AUTOSAR XML (schema 00048)
package /ComponentTypes
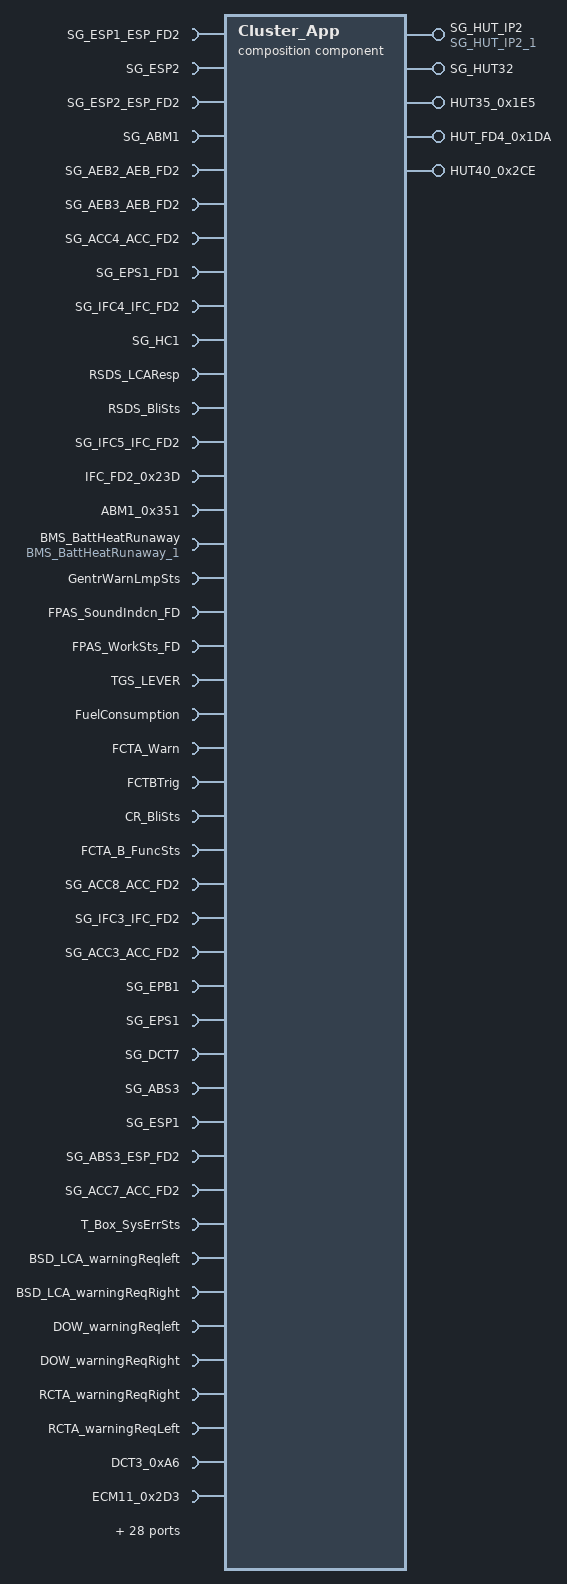
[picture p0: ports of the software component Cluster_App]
  composition sw component type Cluster_App
    33 x require port:
      SG_ESP1_ESP_FD2: nonqueued-receiver-com-spec{data-element=SG_ESP1_ESP_FD2, uses-end-to-end-protection=true, alive-timeout=0.2, enable-update=true, handle-never-received=true, init-value=fields=[BTCActv_0x137:0, CheckSum_ESP1_0x137:0, dummy_ESP_FD2_16:0, dummy_ESP_FD2_17:0, dummy_ESP_FD2_18:0, dummy_ESP_FD2_19:0, dummy_ESP_FD2_20:0, ESP_MasterCylBrkPress_0x137:0, ESP_MasterCylBrkPressVld_0x137:0, ESPActvInfoLmp_0x137:0, ESPBrkLmpCtrl_0x137:0, ESPFailSts_0x137:0, ESPFuncOffSts_0x137:0, MSRActv_0x137:0, PTCActv_0x137:0, RollingCounter_ESP1_0x137:0, VDCActv_0x137:0]}, required-interface=SG_ESP1_ESP_FD2
      SG_ESP2: nonqueued-receiver-com-spec{data-element=SG_ESP2, uses-end-to-end-protection=true, alive-timeout=0.2, enable-update=true, handle-never-received=true, init-value=fields=[DrivingModDis:0, DrivingModReq_ESP:0, TAB_Available:0, TAB_Sts:0, ABAActv_0x145:0, ABAavailable_0x145:0, ABPActv_0x145:0, ABPAvailable_0x145:0, AEBAvailable_0x145:0, AEBBAActv_0x145:0, AEBIBActv_0x145:0, AVHErrSts_0x145:0, AVHSts_0x145:0, AWBActv_0x145:0, AWBAvailable_0x145:0, BrkDskOvrheatd_0x145:0, CDDActv_0x145:0, CDDAvailable_0x145:0, CDPActv_0x145:0, CheckSum_ESP2_0x145:0, dummy_ESP2_0:0, dummy_ESP2_1:0, dummy_ESP2_2:0, dummy_ESP2_3:0, dummy_ESP2_4:0, dummy_ESP2_5:0, dummy_ESP2_6:0, dummy_ESP2_7:0, HDCCtrl_0x145:0, HDCFault_0x145:0, NoBrkForce_0x145:0, RollingCounter_ESP2_0x145:0, VehStandstill_0x145:0]}, required-interface=SG_ESP2
      SG_ESP2_ESP_FD2: nonqueued-receiver-com-spec{data-element=SG_ESP2_ESP_FD2, uses-end-to-end-protection=true, alive-timeout=0.2, enable-update=true, handle-never-received=true, init-value=fields=[ABAActv_0x137:0, ABAavailable_0x137:0, ABPActv_0x137:0, ABPAvailable_0x137:0, AEBAvailable_0x137:0, AEBBAActv_0x137:0, AEBIBActv_0x137:0, AVHErrSts_0x137:0, AVHSts_0x137:0, AWBActv_0x137:0, AWBAvailable_0x137:0, BrkDskOvrheatd_0x137:0, CDDActv_0x137:0, CDDAvailable_0x137:0, CDPActv_0x137:0, CheckSum_ESP2_0x137:0, dummy_ESP_FD2_8:0, dummy_ESP_FD2_9:0, dummy_ESP_FD2_10:0, dummy_ESP_FD2_11:0, dummy_ESP_FD2_12:0, dummy_ESP_FD2_13:0, dummy_ESP_FD2_14:0, dummy_ESP_FD2_15:0, HDCCtrl_0x137:0, HDCFault_0x137:0, NoBrkForce_0x137:0, RollingCounter_ESP2_0x137:0, VehStandstill_0x137:0]}, required-interface=SG_ESP2_ESP_FD2
      SG_ABM1: nonqueued-receiver-com-spec{data-element=SG_ABM1, uses-end-to-end-protection=true, alive-timeout=5, enable-update=true, handle-never-received=true, init-value=fields=[AirbFailLmpCmd:0, CheckSum_ABM1:0, DrvSBR:0, DrvSBR_Visual:0, PassSBR:0, PassSBR_Visual:0, RollingCounter_ABM1:0, SecRowLSBR:0, SecRowLSBR_Visual:0, SecRowMidSBR:0, SecRowMidSBR_Visual:0, SecRowRSBR:0, SecRowRSBR_Visual:0, CrashOutputSts:0, dummy_ABM1_0:0, dummy_ABM1_1:0, dummy_ABM1_2:0, dummy_ABM1_3:0, dummy_ABM1_4:0, dummy_ABM1_5:0]}, required-interface=SG_ABM1
      SG_AEB2_AEB_FD2: nonqueued-receiver-com-spec{data-element=SG_AEB2_AEB_FD2, uses-end-to-end-protection=true, alive-timeout=0.5, enable-update=true, handle-never-received=true, init-value=fields=[AEB_JA_Resp:1, AEB_PedResp:1, AEB_VehResp:1, Checksum_AEB2:0, FCW_Snvty:0, RollingCounter_AEB2:0, dummy_AEB_FD2_8:0, dummy_AEB_FD2_9:0, dummy_AEB_FD2_10:0, dummy_AEB_FD2_11:0, dummy_AEB_FD2_12:0, dummy_AEB_FD2_13:0, dummy_AEB_FD2_14:0]}, required-interface=SG_AEB2_AEB_FD2
      SG_AEB3_AEB_FD2: nonqueued-receiver-com-spec{data-element=SG_AEB3_AEB_FD2, uses-end-to-end-protection=true, alive-timeout=0.5, enable-update=true, handle-never-received=true, init-value=fields=[AEB_JA_Warn:0, AEB_JABrkTrig:0, AEB_JAFuncSts:0, AEB_PedTrig:0, AEB_VehTrig:0, Checksum_AEB3:0, FCW_AEB_PedFctSts:0, FCW_AEB_VehFctSts:0, FCW_Warn:0, RollingCounter_AEB3:0, dummy_AEB_FD2_15:0, dummy_AEB_FD2_16:0, dummy_AEB_FD2_17:0, dummy_AEB_FD2_18:0, dummy_AEB_FD2_19:0, dummy_AEB_FD2_20:0, dummy_AEB_FD2_21:0]}, required-interface=SG_AEB3_AEB_FD2
      SG_ACC4_ACC_FD2: nonqueued-receiver-com-spec{data-element=SG_ACC4_ACC_FD2, uses-end-to-end-protection=true, alive-timeout=1, enable-update=true, handle-never-received=true, init-value=fields=[ACC_FctSts:0, ACC_InterSysInfoDisp:0, ACC_ModDisp:0, ACC_ObjDetecte:0, ACC_SpdSetValue:0, ACC_TakeOverReq:0, ACC_TgtObjBarDisp:0, ACC_TimeGapSet:0, Checksum_ACC4:0, ISL_InterSysInfoDisp:0, RollingCounter_ACC4:0, TJA_ACC_SelSts:0, TJA_ICA_InterSysInfoDisp:0, TJA_ICA_ModDisp:0, CruCha_ModDisp:0, CruChar_InterSysInfoDisp:0, Longctrl_HazActv:0, dummy_ACC_FD2_8:0, dummy_ACC_FD2_9:0, dummy_ACC_FD2_10:0]}, required-interface=SG_ACC4_ACC_FD2
      SG_EPS1_FD1: nonqueued-receiver-com-spec{data-element=SG_EPS1_FD1, uses-end-to-end-protection=true, alive-timeout=0.2, enable-update=true, handle-never-received=true, init-value=fields=[CheckSum_EPS1_0x147:0, dummy_EPS_FD1_0:0, dummy_EPS_FD1_1:0, dummy_EPS_FD1_2:0, dummy_EPS_FD1_3:0, dummy_EPS_FD1_4:0, dummy_EPS_FD1_5:0, dummy_EPS_FD1_6:0, dummy_EPS_FD1_7:0, EPS_FailSts_0x147:0, EPS_SteerMod_0x147:0, EPS_TrqSnsrSts_0x147:0, RollingCounter_EPS1_0x147:0]}, required-interface=SG_EPS1_FD1
      SG_IFC4_IFC_FD2: nonqueued-receiver-com-spec{data-element=SG_IFC4_IFC_FD2, uses-end-to-end-protection=true, alive-timeout=0.5, enable-update=true, handle-never-received=true, init-value=fields=[CameraBlockageSts:0, Checksum_IFC4:0, ELKMainState:0, IFC_Handsoffwarn:0, IFCCalibrationSts:0, LaneAvailability:0, LDW_LKAWarn:0, LSSErrSts:0, LSSFuncSts:0, LSSIntervention:0, RollingCounter_IFC4:0, TJA_FollowSts:0, AESintervention:0, ESSintervention:0, dummy_IFC_FD2_13:0, dummy_IFC_FD2_14:0, dummy_IFC_FD2_15:0, ELKActSts:0, IntelligentEvaActSts:0, LCKStsIndcr:0]}, required-interface=SG_IFC4_IFC_FD2
      SG_HC1: nonqueued-receiver-com-spec{data-element=SG_HC1, uses-end-to-end-protection=true, alive-timeout=1, enable-update=true, handle-never-received=true, init-value=fields=[ADBstatus:0, ALS_FailSts:0, Checksum_HC1:0, HighBeamSts_HC:0, LeftHighBeamFailSts:0, LeftLowBeamFailSts:0, RightHighBeamFailSts:0, RightLowBeamFailSts:0, RollingCounter_HC1:0, dummy_HC1_0:0, dummy_HC1_1:0, dummy_HC1_2:0, dummy_HC1_3:0, dummy_HC1_4:0, dummy_HC1_5:0]}, required-interface=SG_HC1
      RSDS_LCAResp: nonqueued-receiver-com-spec{data-element=RSDS_LCAResp, init-value=0}, required-interface=RSDS_LCAResp
      RSDS_BliSts: nonqueued-receiver-com-spec{data-element=RSDS_BliSts, init-value=0}, required-interface=RSDS_BliSts
      SG_IFC5_IFC_FD2: nonqueued-receiver-com-spec{data-element=SG_IFC5_IFC_FD2, init-value=fields=[Checksum_IFC5:0, IFC_LaneCurve:2047, IFC_LeLane_dy:2496, IFC_LeLaneTyp:0, IFC_NextLeLaneTyp:0, IFC_NextRiLaneTyp:0, IFC_RiLane_dy:2496, IFC_RiLaneTyp:0, RollingCounter_IFC5:0, dummy_IFC_FD2_16:0]}, required-interface=SG_IFC5_IFC_FD2
      IFC_FD2_0x23D: nonqueued-receiver-com-spec{data-element=IFC_FD2_0x23D, init-value=64 x 0}, required-interface=IFC_FD2_0x23D
      ABM1_0x351: nonqueued-receiver-com-spec{data-element=ABM1_0x351, init-value=16 x 0}, required-interface=ABM1_0x351
      BMS_BattHeatRunaway: nonqueued-receiver-com-spec{data-element=BMS_BattHeatRunaway, init-value=0}, required-interface=BMS_BattHeatRunaway_1
      GentrWarnLmpSts: nonqueued-receiver-com-spec{data-element=GentrWarnLmpSts, init-value=0}, required-interface=GentrWarnLmpSts
      FPAS_SoundIndcn_FD: nonqueued-receiver-com-spec{data-element=FPAS_SoundIndcn_FD, init-value=0}, required-interface=FPAS_SoundIndcn_FD
      FPAS_WorkSts_FD: nonqueued-receiver-com-spec{data-element=FPAS_WorkSts_FD, filter=data-filter-type=ALWAYS, init-value=0}, required-interface=FPAS_WorkSts_FD
      TGS_LEVER: nonqueued-receiver-com-spec{data-element=TGS_LEVER, init-value=14}, required-interface=TGS_LEVER
      FuelConsumption: nonqueued-receiver-com-spec{data-element=FuelConsumption, init-value=0}, required-interface=FuelConsumption
      FCTA_Warn: nonqueued-receiver-com-spec{data-element=FCTA_Warn, init-value=0}, required-interface=FCTA_Warn
      FCTBTrig: nonqueued-receiver-com-spec{data-element=FCTBTrig, init-value=0}, required-interface=FCTBTrig
      CR_BliSts: nonqueued-receiver-com-spec{data-element=CR_BliSts, init-value=0}, required-interface=CR_BliSts
      FCTA_B_FuncSts: nonqueued-receiver-com-spec{data-element=FCTA_B_FuncSts, init-value=0}, required-interface=FCTA_B_FuncSts
      SG_ACC8_ACC_FD2: nonqueued-receiver-com-spec{data-element=SG_ACC8_ACC_FD2, init-value=fields=[ADAS_DriverInloop_Monitor:0, Checksum_ACC8:0, HWA_InterSysInfoDisp:0, HWA_LaneChange:0, HWA_LaneChangeReq:0, HWA_ModDisp:0, HWA_warning:0, Longctrl_HCUTrqReq_DVR:0, RollingCounter_ACC8:0, dummy_ACC_FD2_11:0, dummy_ACC_FD2_12:0, dummy_ACC_FD2_13:0, dummy_ACC_FD2_14:0, dummy_ACC_FD2_15:0]}, required-interface=SG_ACC8_ACC_FD2
      SG_IFC3_IFC_FD2: nonqueued-receiver-com-spec{data-element=SG_IFC3_IFC_FD2, init-value=fields=[AESErrSts:0, AESResp:0, AESSts:0, Checksum_IFC3:0, ELKResp:0, ESS_Pedresp:0, ESS_Vehresp:0, ESSErrSts:0, ESSSts:0, IFCHUTInterface:0, IntelligentEvaResp:0, LCKResp:0, LDW_LKA_Snvty:0, LDWResp:0, LKAResp:0, LSSResp:0, LSSWarnFormResp:0, RollingCounter_IFC3:0, dummy_IFC_FD2_8:0, dummy_IFC_FD2_9:0, dummy_IFC_FD2_10:0, dummy_IFC_FD2_11:0, dummy_IFC_FD2_12:0]}, required-interface=SG_IFC3_IFC_FD2
      SG_ACC3_ACC_FD2: nonqueued-receiver-com-spec{data-element=SG_ACC3_ACC_FD2, init-value=fields=[ALC_InterSysInfoDisp:0, ALC_Resp:0, Checksum_ACC3:0, HWA_Resp:0, HWA_SnvtySet_Resp:0, ICA_HandsOffResp:0, ISL_Resp:0, Longctrl_Decel_Req_DVR:0, Longctrl_Decel_ReqValue_DVR:0, Longctrl_DecelToStopReq_DVR:0, Longctrl_DrvOFF_Req_DVR:0, Longctrl_EngTrqReq_DVR:32767, Longctrl_EngTrqReqActive_DVR:0, Longctrl_HCUTrqReqActive_DVR:0, Longctrl_ModSts_DVR:0, Longctrl_ParkShiftReq_DVR:0, Longctrl_VehHldReq_DVR:0, RollingCounter_ACC3:0, dummy_ACC_FD2_4:0, dummy_ACC_FD2_5:0, dummy_ACC_FD2_6:0, dummy_ACC_FD2_7:0]}, required-interface=SG_ACC3_ACC_FD2
      SG_EPB1: nonqueued-receiver-com-spec{data-element=SG_EPB1, uses-end-to-end-protection=true, alive-timeout=0.2, enable-update=true, handle-never-received=true, init-value=fields=[CheckSum_EPB1:0, EPBErrSts:0, EPBRedLmpSts:0, EPBSts:0, EPBTextDisp:0, PressBrakePedalPointOut:0, RollingCounter_EPB1:0, dummy_EPB1_0:0, dummy_EPB1_1:0, dummy_EPB1_2:0, dummy_EPB1_3:0, dummy_EPB1_4:0, dummy_EPB1_5:0, dummy_EPB1_6:0, dummy_EPB1_7:0]}, required-interface=SG_EPB1
      SG_EPS1: nonqueued-receiver-com-spec{data-element=SG_EPS1, uses-end-to-end-protection=true, alive-timeout=0.2, enable-update=true, handle-never-received=true, init-value=fields=[CheckSum_EPS1_0x168:0, dummy_EPS1_0:0, dummy_EPS1_1:0, dummy_EPS1_2:0, dummy_EPS1_3:0, dummy_EPS1_4:0, dummy_EPS1_5:0, dummy_EPS1_6:0, dummy_EPS1_7:0, EPS_FailSts_0x168:0, EPS_SteerMod_0x168:0, EPS_TrqSnsrSts_0x168:1, RollingCounter_EPS1_0x168:0]}, required-interface=SG_EPS1
      SG_DCT7: nonqueued-receiver-com-spec{data-element=SG_DCT7, uses-end-to-end-protection=true, alive-timeout=0.5, enable-update=true, handle-never-received=true, init-value=fields=[CheckSum_DCT7:0, DCT_PrsBrk_Warn:0, DCT_RaceModeSts:0, DCT_ShftNotAlwd_Warn:0, DCT_ShftRecom_M:0, DrvAutoGearDisp:0, DrvWarnMsg:0, RollingCounter_DCT7:0, DrvFaiMsg_0x235:0, DrvGearDispSts_0x235:0, DrvModDisp_0x235:0, DrvModDispSts_0x235:0, dummy_DCT7_0:0, dummy_DCT7_1:0, dummy_DCT7_2:0, dummy_DCT7_3:0, dummy_DCT7_4:0, dummy_DCT7_5:0]}, required-interface=SG_DCT7
      SG_ABS3: nonqueued-receiver-com-spec{data-element=SG_ABS3, uses-end-to-end-protection=true, alive-timeout=0.2, enable-update=true, handle-never-received=true, init-value=fields=[ABSActv_0x265:0, ABSFailSts_0x265:1, CheckSum_ABS3_0x265:0, dummy_ABS3_0:0, dummy_ABS3_1:0, dummy_ABS3_2:0, dummy_ABS3_3:0, EBDActv_0x265:0, EBDFailSts_0x265:0, RollingCounter_ABS3_0x265:0, VehOdoInfo_0x265:0, VehOdoInfoSts_0x265:1, VehSpd_0x265:0, VehSpdVld_0x265:0]}, required-interface=SG_ABS3
      SG_ESP1: nonqueued-receiver-com-spec{data-element=SG_ESP1, uses-end-to-end-protection=true, alive-timeout=0.2, enable-update=true, handle-never-received=true, init-value=fields=[BTCActv_0x149:0, CheckSum_ESP1_0x149:0, dummy_ESP1_0:0, dummy_ESP1_1:0, dummy_ESP1_2:0, dummy_ESP1_3:0, dummy_ESP1_4:0, ESP_MasterCylBrkPress_0x149:0, ESP_MasterCylBrkPressVld_0x149:1, ESPActvInfoLmp_0x149:0, ESPBrkLmpCtrl_0x149:0, ESPFailSts_0x149:0, ESPFuncOffSts_0x149:0, MSRActv_0x149:0, PTCActv_0x149:0, RollingCounter_ESP1_0x149:0, VDCActv_0x149:0]}, required-interface=SG_ESP1
    provide port SG_HUT_IP2: nonqueued-sender-com-spec{data-element=SG_HUT_IP2, uses-end-to-end-protection=true, init-value=fields=[CheckSum_IP2:0, IP_ABMWarnLmpFailrSts:0, IP_ACCErr:0, IP_BattChrgLmpSts:0, IP_DrvSeatBeltWarnLmpFailSts:0, IP_EngOilPressLowLmpSts:0, IP_Err:0, IP_FuelLvlInfo:0, IP_FuelLvlLowLmpSts:0, IP_PassSeatBeltWarnLmpFailSts:0, IP_VehSpdUnit:0, IP_VehTotDistance:0, IP_VehTotDistanceValid:0, IP_VINcompr:0, RollingCounter_IP2:0]}, provided-interface=SG_HUT_IP2_1
    11 x require port:
      SG_ABS3_ESP_FD2: nonqueued-receiver-com-spec{data-element=SG_ABS3_ESP_FD2, uses-end-to-end-protection=true, alive-timeout=0.2, enable-update=true, handle-never-received=true, init-value=fields=[ABSActv_0x137:0, ABSFailSts_0x137:1, CheckSum_ABS3_0x137:0, dummy_ESP_FD2_37:0, dummy_ESP_FD2_38:0, dummy_ESP_FD2_39:0, dummy_ESP_FD2_40:0, EBDActv_0x137:0, EBDFailSts_0x137:0, RollingCounter_ABS3_0x137:0, VehOdoInfo_0x137:0, VehOdoInfoSts_0x137:1, VehSpd_0x137:0, VehSpdVld_0x137:0]}, required-interface=SG_ABS3_ESP_FD2
      SG_ACC7_ACC_FD2: nonqueued-receiver-com-spec{data-element=SG_ACC7_ACC_FD2, uses-end-to-end-protection=true, alive-timeout=1, enable-update=true, handle-never-received=true, init-value=fields=[ACC_LeTargrtDection:0, ACC_LeTgtDx:0, ACC_LeTgtDy:0, ACC_LeTgtTyp:0, ACC_RiTargrtDetn:0, ACC_RiTgtDx:0, ACC_RiTgtDy:0, ACC_RiTgtTyp:0, Checksum_ACC7:0, dummy_ACC_FD2_19:0, dummy_ACC_FD2_20:0, Request_driveoff:0, RollingCounter_ACC7:0]}, required-interface=SG_ACC7_ACC_FD2
      T_Box_SysErrSts: nonqueued-receiver-com-spec{data-element=T_Box_SysErrSts, init-value=0}, required-interface=T_Box_SysErrSts
      BSD_LCA_warningReqleft: nonqueued-receiver-com-spec{data-element=BSD_LCA_warningReqleft, init-value=0}, required-interface=BSD_LCA_warningReqleft
      BSD_LCA_warningReqRight: nonqueued-receiver-com-spec{data-element=BSD_LCA_warningReqRight, init-value=0}, required-interface=BSD_LCA_warningReqRight
      DOW_warningReqleft: nonqueued-receiver-com-spec{data-element=DOW_warningReqleft, init-value=0}, required-interface=DOW_warningReqleft
      DOW_warningReqRight: nonqueued-receiver-com-spec{data-element=DOW_warningReqRight, init-value=0}, required-interface=DOW_warningReqRight
      RCTA_warningReqRight: nonqueued-receiver-com-spec{data-element=RCTA_warningReqRight, init-value=0}, required-interface=RCTA_warningReqRight
      RCTA_warningReqLeft: nonqueued-receiver-com-spec{data-element=RCTA_warningReqLeft, init-value=0}, required-interface=RCTA_warningReqLeft
      DCT3_0xA6: nonqueued-receiver-com-spec{data-element=DCT3_0xA6, init-value=8 x 0}, required-interface=DCT3_0xA6
      ECM11_0x2D3: nonqueued-receiver-com-spec{data-element=ECM11_0x2D3, init-value=8 x 0}, required-interface=ECM11_0x2D3
    provide port SG_HUT32: nonqueued-sender-com-spec{data-element=SG_HUT32, uses-end-to-end-protection=true, init-value=fields=[CheckSum_HUT32:0, ContnPrkgReq:0, ContnPrkgReqValid:0, DetVideoLost:0, PrkgCtrlModReq:0, PrkgCtrlModReqValid:0, PrkStraightContinueReq_HUT:0, PrkStraightModSel_HUT:0, PrkStraightStrtReq_HUT:0, PrkStraightSts_HUT:0, PrkStraightSuspendOrFinishReq_HUT:0, PrkStraightSwtReq_HUT:0, PrkStraightVehStrtReq_HUT_Valid:0, RollingCounter_HUT32:0, ScrnOpSts:0, VolLampDispSts:0, XLvl:2047, YLvl:2047]}, provided-interface=SG_HUT32
    8 x require port:
      ACC_FD4_0x2B8: nonqueued-receiver-com-spec{data-element=ACC_FD4_0x2B8, alive-timeout=1, enable-update=true, filter=data-filter-type=ALWAYS, handle-never-received=true, init-value=64 x 0}, required-interface=ACC_FD4_0x2B8
      SG_ACC6_ACC_FD2: nonqueued-receiver-com-spec{data-element=SG_ACC6_ACC_FD2, uses-end-to-end-protection=true, alive-timeout=1, enable-update=true, filter=data-filter-type=ALWAYS, handle-never-received=true, init-value=fields=[ACC_EgoStatus:0, ACC_PotentialTgtDetn:0, ACC_PotentialTgtDx:0, ACC_PotentialTgtDy:0, ACC_PotentialTgtTyp:0, ACC_RlvTgtDetn:0, ACC_RlvTgtDx:0, ACC_RlvTgtDy:0, ACC_RlvTgtTyp:0, Checksum_ACC6:0, dummy_ACC_FD2_16:0, dummy_ACC_FD2_17:0, dummy_ACC_FD2_18:0, RollingCounter_ACC6:0]}, required-interface=SG_ACC6_ACC_FD2
      SG_BMS4: nonqueued-receiver-com-spec{data-element=SG_BMS4, uses-end-to-end-protection=true, alive-timeout=0.1, enable-update=true, filter=data-filter-type=ALWAYS, handle-never-received=true, init-value=fields=[BMS_BattPoweErr:0, BMS_ErrCategory:0, BMS_PackCurr:0, BMS_PackVolt:178, BMS_PowerDownCmplt:0, CheckSum_BMS4:0, dummy_BMS4_0:0, dummy_BMS4_1:0, dummy_BMS4_2:0, dummy_BMS4_3:0, dummy_BMS4_4:0, RollingCounter_BMS4:0]}, required-interface=SG_BMS4
      SG_HCU_HP5: nonqueued-receiver-com-spec{data-element=SG_HCU_HP5, uses-end-to-end-protection=true, alive-timeout=0.5, enable-update=true, filter=data-filter-type=ALWAYS, handle-never-received=true, init-value=fields=[Checksum_HCU_HP5:0, DrvFaiMsg_0x201:0, DrvGearDisp:0, DrvGearDispSts_0x201:0, DrvModDisp_0x201:0, DrvModDispSts_0x201:0, dummy_HCU_HP5_0:0, dummy_HCU_HP5_1:0, dummy_HCU_HP5_2:0, dummy_HCU_HP5_3:0, dummy_HCU_HP5_4:0, HCU_EnrgFlowInd_DHT:0, HCU_PrsBrkWarn:0, HCU_ShftNotAlwd_Warn:0, RollingCounter_HCU_HP5:0]}, required-interface=SG_HCU_HP5
      SG_HCU_PT4: nonqueued-receiver-com-spec{data-element=SG_HCU_PT4, uses-end-to-end-protection=true, alive-timeout=1, enable-update=true, filter=data-filter-type=ALWAYS, handle-never-received=true, init-value=fields=[CarWashMode_Sts:0, CarWashMode_StsDisp:0, Checksum_HCU_PT4:0, dummy_HCU_PT4_0:0, dummy_HCU_PT4_1:0, dummy_HCU_PT4_2:0, dummy_HCU_PT4_3:0, dummy_HCU_PT4_4:0, dummy_HCU_PT4_5:0, dummy_HCU_PT4_6:0, dummy_HCU_PT4_7:0, HCU_ACStsReq:2, HCU_BattPowerRedWarn:0, HCU_ConnectChrgLine_Indcn:0, HCU_EgyRecFB:0, HCU_EnerSavePowerMod:0, HCU_InhbChrgInfo:0, HCU_OilTankCoverSts:0, HCU_OPDFail:0, HCU_RefuReq:0, HCU_RemoveChrgLine_Indcn:0, HCU_Shift_P_Indcn:0, HCU_SOCLow_Indcn:0, HCU_WadeModeSetSts:0, OPDParkWarnReq:0, RollingCounter_HCU_PT4:0]}, required-interface=SG_HCU_PT4
      SG_HCU_PT7: nonqueued-receiver-com-spec{data-element=SG_HCU_PT7, uses-end-to-end-protection=true, alive-timeout=0.5, enable-update=true, filter=data-filter-type=ALWAYS, handle-never-received=true, init-value=fields=[CheckSum_HCU_PT7:0, dummy_HCU_PT7_0:0, dummy_HCU_PT7_1:0, dummy_HCU_PT7_2:0, dummy_HCU_PT7_3:0, dummy_HCU_PT7_4:0, dummy_HCU_PT7_5:0, dummy_HCU_PT7_6:0, HCU_12VSysErr_1:0, HCU_12VSysErr_2:0, HCU_12VSysErrLmpSts:0, HCU_EnrgFlowInd:0, HCU_HybSysErr_1:0, HCU_HybSysErr_2:0, HCU_HybSysErr_3:0, HCU_HybSysErr_4:0, HCU_HybSysErr_5:0, HCU_HybSysErr_6:0, HCU_HybSysErr_7:0, HCU_HybSysErrLmpSts:0, HCU_ModSwtFail:0, HCU_OPDLmpSts:0, HCU_OPDSts:0, HCU_PowerRedWarnLmpCmd:0, HCU_RdyLmpSts:0, RollingCounter_HCU_PT7:0]}, required-interface=SG_HCU_PT7
      SG_DHT_FD1: nonqueued-receiver-com-spec{data-element=SG_DHT_FD1, uses-end-to-end-protection=true, alive-timeout=0.1, enable-update=true, filter=data-filter-type=ALWAYS, handle-never-received=true, init-value=fields=[CheckSum_DHT1:0, dummy_DHT_FD1_8:0, dummy_DHT_FD1_9:0, dummy_DHT_FD1_10:0, dummy_DHT_FD1_11:0, dummy_DHT_FD1_12:0, dummy_DHT_FD1_13:0, RollingCounter_DHT1:0, TCU_ClutchHotWarning:0, TCU_ErrCategory:0]}, required-interface=SG_DHT_FD1
      SG_IFC6_IFC_FD2: nonqueued-receiver-com-spec{data-element=SG_IFC6_IFC_FD2, uses-end-to-end-protection=true, alive-timeout=0.5, enable-update=true, filter=data-filter-type=ALWAYS, handle-never-received=true, init-value=fields=[Checksum_IFC6:0, dummy_IFC_FD2_17:0, dummy_IFC_FD2_18:0, dummy_IFC_FD2_19:0, dummy_IFC_FD2_20:0, IFC_NextLeLane_dy:2496, IFC_NextRiLane_dy:2496, RollingCounter_IFC6:0]}, required-interface=SG_IFC6_IFC_FD2
    provide port HUT35_0x1E5: nonqueued-sender-com-spec{data-element=HUT35_0x1E5, init-value=8 x 0}, provided-interface=HUT35_0x1E5
    provide port HUT_FD4_0x1DA: nonqueued-sender-com-spec{data-element=HUT_FD4_0x1DA, init-value=64 x 0}, provided-interface=HUT_FD4_0x1DA
    require port HAP_FD6_0x289: nonqueued-receiver-com-spec{data-element=HAP_FD6_0x289, uses-end-to-end-protection=true, alive-timeout=1, enable-update=true, filter=data-filter-type=ALWAYS, handle-never-received=true, init-value=64 x 0}, required-interface=HAP_FD6_0x289
    require port HAP_FD7_0x29B: nonqueued-receiver-com-spec{data-element=HAP_FD7_0x29B, alive-timeout=1, enable-update=true, filter=data-filter-type=ALWAYS, handle-never-received=true, init-value=64 x 0}, required-interface=HAP_FD7_0x29B
    provide port HUT40_0x2CE: nonqueued-sender-com-spec{data-element=HUT40_0x2CE, init-value=8 x 0}, provided-interface=HUT40_0x2CE
    18 x require port:
      HCM_L1_0x308: nonqueued-receiver-com-spec{data-element=HCM_L1_0x308, alive-timeout=2, enable-update=true, filter=data-filter-type=ALWAYS, handle-never-received=true, init-value=8 x 0}, required-interface=HCM_L1_0x308
      HCM_R1_0x30D: nonqueued-receiver-com-spec{data-element=HCM_R1_0x30D, alive-timeout=2, enable-update=true, filter=data-filter-type=ALWAYS, handle-never-received=true, init-value=8 x 0}, required-interface=HCM_R1_0x30D
      BMS22_0x3BF: nonqueued-receiver-com-spec{data-element=BMS22_0x3BF, alive-timeout=10, enable-update=true, filter=data-filter-type=ALWAYS, handle-never-received=true, init-value=8 x 0}, required-interface=BMS22_0x3BF
      BMS8_0x285: nonqueued-receiver-com-spec{data-element=BMS8_0x285, alive-timeout=1, enable-update=true, filter=data-filter-type=ALWAYS, handle-never-received=true, init-value=8 x 0}, required-interface=BMS8_0x285
      BMS_FD14_0x1E3: nonqueued-receiver-com-spec{data-element=BMS_FD14_0x1E3, init-value=8 x 0}, required-interface=BMS_FD14_0x1E3
      HCU_FD1_0x60: nonqueued-receiver-com-spec{data-element=HCU_FD1_0x60, alive-timeout=0.1, enable-update=true, filter=data-filter-type=ALWAYS, handle-never-received=true, init-value=64 x 0}, required-interface=HCU_FD1_0x60
      HCU_HC3_0x268: nonqueued-receiver-com-spec{data-element=HCU_HC3_0x268, alive-timeout=0.5, enable-update=true, filter=data-filter-type=ALWAYS, handle-never-received=true, init-value=8 x 0}, required-interface=HCU_HC3_0x268
      HCU_HC8_0x1E2: nonqueued-receiver-com-spec{data-element=HCU_HC8_0x1E2, filter=data-filter-type=ALWAYS, init-value=8 x 0}, required-interface=HCU_HC8_0x1E2
      HCU_HP5_0x201: nonqueued-receiver-com-spec{data-element=HCU_HP5_0x201, alive-timeout=0.5, enable-update=true, filter=data-filter-type=ALWAYS, handle-never-received=true, init-value=8 x 0}, required-interface=HCU_HP5_0x201
      HCU_HP6_0x11A: nonqueued-receiver-com-spec{data-element=HCU_HP6_0x11A, alive-timeout=0.2, enable-update=true, filter=data-filter-type=ALWAYS, handle-never-received=true, init-value=8 x 0}, required-interface=HCU_HP6_0x11A
      FPAS_WorkSts: nonqueued-receiver-com-spec{data-element=FPAS_WorkSts, alive-timeout=1, enable-update=true, filter=data-filter-type=ALWAYS, handle-never-received=true, init-value=0}, required-interface=FPAS_WorkSts
      FPAS_SoundIndcn: nonqueued-receiver-com-spec{data-element=FPAS_SoundIndcn, alive-timeout=1, enable-update=true, filter=data-filter-type=ALWAYS, handle-never-received=true, init-value=0}, required-interface=FPAS_SoundIndcn
      RPAS_SoundIndcn: nonqueued-receiver-com-spec{data-element=RPAS_SoundIndcn, alive-timeout=1, enable-update=true, filter=data-filter-type=ALWAYS, handle-never-received=true, init-value=0}, required-interface=RPAS_SoundIndcn
      RPAS_WorkSts: nonqueued-receiver-com-spec{data-element=RPAS_WorkSts, alive-timeout=1, enable-update=true, filter=data-filter-type=ALWAYS, handle-never-received=true, init-value=0}, required-interface=RPAS_WorkSts
      LADBstatus: nonqueued-receiver-com-spec{data-element=LADBstatus, alive-timeout=2, enable-update=true, filter=data-filter-type=ALWAYS, handle-never-received=true, init-value=0}, required-interface=LADBstatus
      RADBstatus: nonqueued-receiver-com-spec{data-element=RADBstatus, alive-timeout=2, enable-update=true, filter=data-filter-type=ALWAYS, handle-never-received=true, init-value=0}, required-interface=RADBstatus
      LHiBeamSts: nonqueued-receiver-com-spec{data-element=LHiBeamSts, alive-timeout=2, enable-update=true, filter=data-filter-type=ALWAYS, handle-never-received=true, init-value=0}, required-interface=LHiBeamSts
      RHiBeamSts: nonqueued-receiver-com-spec{data-element=RHiBeamSts, alive-timeout=2, enable-update=true, filter=data-filter-type=ALWAYS, handle-never-received=true, init-value=0}, required-interface=RHiBeamSts
    component Common_Normal: type=Common_Normal
    component Common_GateWay: type=Common_GateWay
    component Common_Safety: type=Common_Safety
    delegate Common_Safety.SG_ESP1_ESP_FD2 <-> outer port SG_ESP1_ESP_FD2
    delegate Common_Normal.SG_IFC4_IFC_FD2 <-> outer port SG_IFC4_IFC_FD2
    connect Common_Normal.ppCS_SWCNormal_DM_API_vGetDrvModTTStatus -> Common_Normal.rpCS_SWCNormal_DM_API_vGetDrvModTTStatus
    connect Common_Normal.ppCS_SWCNormal_DM_API_vGetDrvModWarningStatus -> Common_Normal.rpCS_SWCNormal_DM_API_vGetDrvModWarningStatus
    connect Common_Normal.ppSR_SWCNormal_SpeedoInfo -> Common_Normal.rpSR_SWCNormal_SpeedoInfo
    connect Common_Normal.ppSR_SWCNormal_TachoInfo -> Common_Normal.rpSR_SWCNormal_TachoInfo
    connect Common_Normal.ppSR_SWCNormal_OdoParament -> Common_Normal.rpSR_SWCNormal_OdoParament
    connect Common_Normal.ppSR_SWCNormal_Fuel_Set_Module_Data -> Common_Normal.rpSR_SWCNormal_Fuel_Set_Module_Data
    connect Common_Normal.ppSR_SWCNormal_TC_Module_Output_Data -> Common_Normal.rpSR_SWCNormal_TC_Module_Output_Data
    connect Common_Normal.ppCS_SWCNormal_Reset_TC_Module_Data -> Common_Normal.rpCS_SWCNormal_Reset_TC_Module_Data
    connect Common_Normal.svCS_SWCNormal_ReceiveMenuSetting -> Common_GateWay.rcCS_SWCNormal_ReceiveMenuSetting
    connect Common_Normal.svCS_SWCNormal_HMIResetTC -> Common_GateWay.rcCS_SWCNormal_HMIResetTC
    delegate Common_Normal.SG_HC1 <-> outer port SG_HC1
    delegate Common_Safety.SG_ESP1 <-> outer port SG_ESP1
    delegate Common_GateWay.SG_HUT_IP2 <-> outer port SG_HUT_IP2
    delegate Common_GateWay.SG_ACC7_ACC_FD2 <-> outer port SG_ACC7_ACC_FD2
    delegate Common_Normal.T_Box_SysErrSts <-> outer port T_Box_SysErrSts
    delegate Common_Normal.BSD_LCA_warningReqRight <-> outer port BSD_LCA_warningReqRight
    delegate Common_Normal.BSD_LCA_warningReqleft <-> outer port BSD_LCA_warningReqleft
    delegate Common_Normal.DOW_warningReqleft <-> outer port DOW_warningReqleft
    delegate Common_Normal.DOW_warningReqRight <-> outer port DOW_warningReqRight
    delegate Common_Normal.RCTA_warningReqLeft <-> outer port RCTA_warningReqLeft
    delegate Common_Normal.RCTA_warningReqRight <-> outer port RCTA_warningReqRight
    delegate Common_Safety.SG_AEB2_AEB_FD2 <-> outer port SG_AEB2_AEB_FD2
    delegate Common_Safety.SG_AEB3_AEB_FD2 <-> outer port SG_AEB3_AEB_FD2
    delegate Common_Safety.SG_EPS1_FD1 <-> outer port SG_EPS1_FD1
    delegate Common_Safety.SG_ESP2_ESP_FD2 <-> outer port SG_ESP2_ESP_FD2
    delegate Common_Safety.SG_ABM1 <-> outer port SG_ABM1
    delegate Common_Safety.SG_ABS3_ESP_FD2 <-> outer port SG_ABS3_ESP_FD2
    delegate Common_Safety.SG_DCT7 <-> outer port SG_DCT7
    delegate Common_Safety.SG_EPB1 <-> outer port SG_EPB1
    delegate Common_Safety.SG_EPS1 <-> outer port SG_EPS1
    delegate Common_Safety.SG_ESP2 <-> outer port SG_ESP2
    delegate Common_Safety.SG_ABS3 <-> outer port SG_ABS3
    delegate Common_GateWay.DCT3_0xA6 <-> outer port DCT3_0xA6
    delegate Common_GateWay.ECM11_0x2D3 <-> outer port ECM11_0x2D3
    delegate Common_GateWay.SG_HUT32 <-> outer port SG_HUT32
    delegate Common_GateWay.ACC_FD4_0x2B8 <-> outer port ACC_FD4_0x2B8
    delegate Common_GateWay.SG_ACC6_ACC_FD2 <-> outer port SG_ACC6_ACC_FD2
    delegate Common_GateWay.SG_ACC8_ACC_FD2 <-> outer port SG_ACC8_ACC_FD2
    delegate Common_GateWay.SG_ACC3_ACC_FD2 <-> outer port SG_ACC3_ACC_FD2
    delegate Common_GateWay.SG_ACC4_ACC_FD2 <-> outer port SG_ACC4_ACC_FD2
    delegate Common_GateWay.HUT35_0x1E5 <-> outer port HUT35_0x1E5
    delegate Common_GateWay.HUT_FD4_0x1DA <-> outer port HUT_FD4_0x1DA
    delegate Common_GateWay.HAP_FD6_0x289 <-> outer port HAP_FD6_0x289
    delegate Common_GateWay.HUT40_0x2CE <-> outer port HUT40_0x2CE
    delegate Common_GateWay.HCM_R1_0x30D <-> outer port HCM_R1_0x30D
    delegate Common_GateWay.HCM_L1_0x308 <-> outer port HCM_L1_0x308
    delegate Common_GateWay.HAP_FD7_0x29B <-> outer port HAP_FD7_0x29B
    delegate Common_GateWay.BMS8_0x285 <-> outer port BMS8_0x285
    delegate Common_GateWay.BMS22_0x3BF <-> outer port BMS22_0x3BF
    delegate Common_GateWay.BMS_FD14_0x1E3 <-> outer port BMS_FD14_0x1E3
    delegate Common_GateWay.HCU_HC8_0x1E2 <-> outer port HCU_HC8_0x1E2
    delegate Common_GateWay.HCU_HC3_0x268 <-> outer port HCU_HC3_0x268
    delegate Common_GateWay.HCU_FD1_0x60 <-> outer port HCU_FD1_0x60
    delegate Common_Safety.SG_IFC6_IFC_FD2 <-> outer port SG_IFC6_IFC_FD2
    delegate Common_Safety.SG_HCU_PT4 <-> outer port SG_HCU_PT4
    delegate Common_Safety.SG_HCU_PT7 <-> outer port SG_HCU_PT7
    delegate Common_Safety.SG_HCU_HP5 <-> outer port SG_HCU_HP5
    delegate Common_Safety.SG_DHT_FD1 <-> outer port SG_DHT_FD1
    delegate Common_Safety.SG_BMS4 <-> outer port SG_BMS4
    delegate Common_GateWay.HCU_HP5_0x201 <-> outer port HCU_HP5_0x201
    delegate Common_GateWay.HCU_HP6_0x11A <-> outer port HCU_HP6_0x11A
    delegate Common_Normal.FPAS_SoundIndcn <-> outer port FPAS_SoundIndcn
    delegate Common_Normal.FPAS_WorkSts <-> outer port FPAS_WorkSts
    delegate Common_Normal.RPAS_WorkSts <-> outer port RPAS_WorkSts
    delegate Common_Normal.RPAS_SoundIndcn <-> outer port RPAS_SoundIndcn
    delegate Common_Normal.LHiBeamSts <-> outer port LHiBeamSts
    delegate Common_Normal.RHiBeamSts <-> outer port RHiBeamSts
    delegate Common_Normal.LADBstatus <-> outer port LADBstatus
    delegate Common_Normal.RADBstatus <-> outer port RADBstatus
